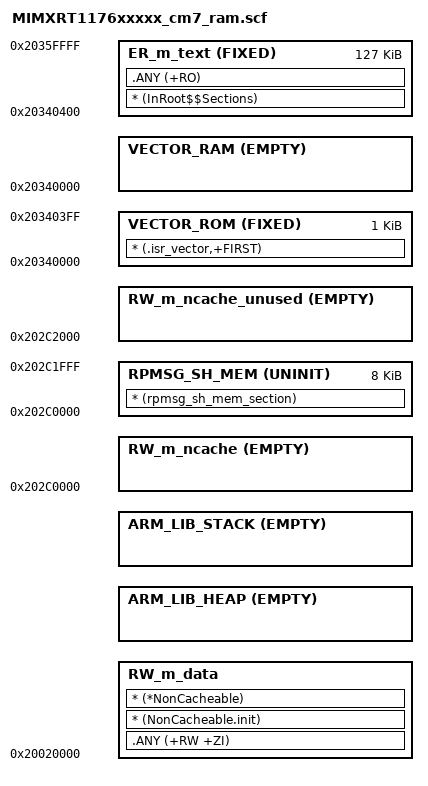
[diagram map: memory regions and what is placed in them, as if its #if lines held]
#!armclang --target=arm-arm-none-eabi -mcpu=cortex-m7 -E -x c
/*
** ###################################################################
**     Processors:          MIMXRT1176AVM8A_cm7
**                          MIMXRT1176CVM8A_cm7
**                          MIMXRT1176DVMAA_cm7
**
**     Compiler:            Keil ARM C/C++ Compiler
**     Reference manual:    IMXRT1170RM, Rev E, 12/2019
**     Version:             rev. 0.1, 2018-03-05
**     Build:               b200507
**
**     Abstract:
**         Linker file for the Keil ARM C/C++ Compiler
**
**     Copyright 2016 Freescale Semiconductor, Inc.
**     Copyright 2016-2020 NXP
**     All rights reserved.
**
**     SPDX-License-Identifier: BSD-3-Clause
**
**     http:                 www.nxp.com
**     mail:                 support@nxp.com
**
** ###################################################################
*/

#define m_interrupts_start             0x20340000
#define m_interrupts_size              0x00000400

#define m_text_start                   0x20340400
#define m_text_size                    0x0001FC00

#define m_data_start                   0x20020000
#define m_data_size                    0x00020000

#if (defined(__use_shmem__))
  #define m_rpmsg_sh_mem_start         0x202C0000
  #define m_rpmsg_sh_mem_size          0x00002000

  #define m_data2_start                0x202C2000
  #define m_data2_size                 0x0007E000
#else
  #define m_data2_start                0x202C0000
  #define m_data2_size                 0x00080000
#endif

/* Sizes */
#if (defined(__stack_size__))
  #define Stack_Size                   __stack_size__
#else
  #define Stack_Size                   0x0400
#endif

#if (defined(__heap_size__))
  #define Heap_Size                    __heap_size__
#else
  #define Heap_Size                    0x0400
#endif

LR_m_text m_interrupts_start m_text_start+m_text_size-m_interrupts_start {   ; load region size_region
  VECTOR_ROM m_interrupts_start FIXED m_interrupts_size { ; load address = execution address
    * (.isr_vector,+FIRST)
  }
  ER_m_text m_text_start FIXED m_text_size { ; load address = execution address
    * (InRoot$$Sections)
    .ANY (+RO)
  }
  VECTOR_RAM m_interrupts_start EMPTY 0 {
  }
  RW_m_data m_data_start m_data_size-Stack_Size-Heap_Size { ; RW data
    .ANY (+RW +ZI)
    * (NonCacheable.init)
    * (*NonCacheable)
  }
  ARM_LIB_HEAP +0 EMPTY Heap_Size {    ; Heap region growing up
  }
  ARM_LIB_STACK m_data_start+m_data_size EMPTY -Stack_Size { ; Stack region growing down
  }
#if (defined(__use_shmem__))
  RW_m_ncache m_rpmsg_sh_mem_start EMPTY 0 {
  }
  RPMSG_SH_MEM m_rpmsg_sh_mem_start UNINIT m_rpmsg_sh_mem_size { ; Shared memory used by RPMSG
    * (rpmsg_sh_mem_section)
  }
  RW_m_ncache_unused m_rpmsg_sh_mem_start+m_rpmsg_sh_mem_size EMPTY 0 { ; Empty region added for MPU configuration
  }
#else
  RW_m_ncache m_data2_start EMPTY 0 {
  }
  RW_m_ncache_unused +0 EMPTY m_data2_size-ImageLength(RW_m_ncache) { ; Empty region added for MPU configuration
  }
#endif
}
